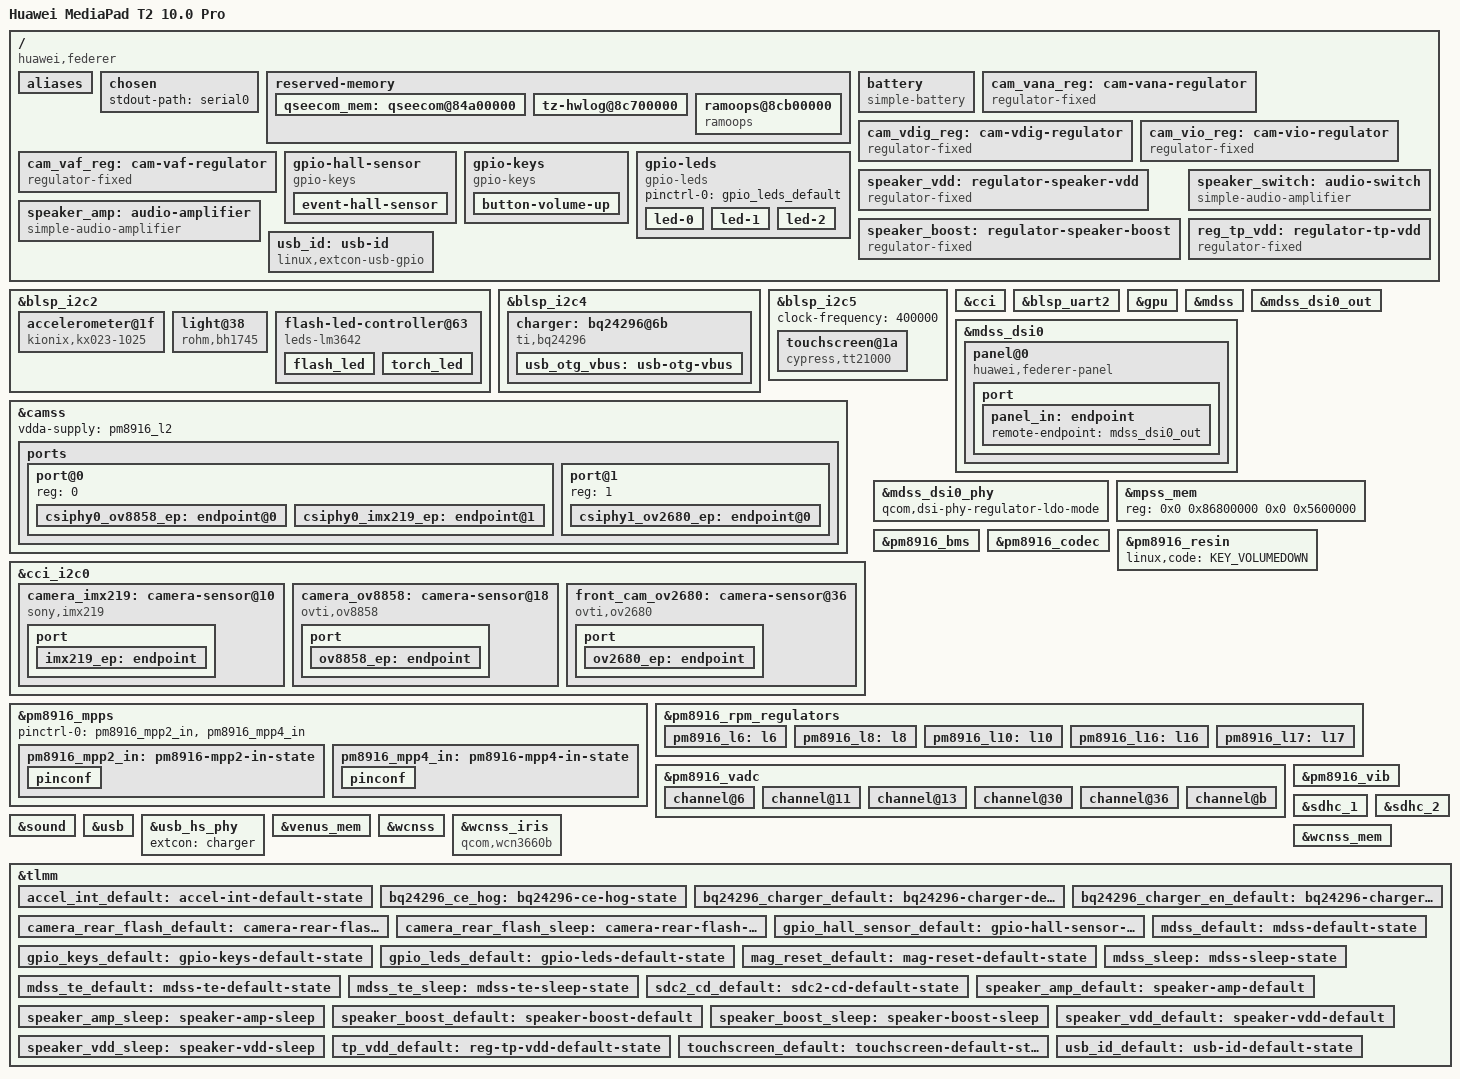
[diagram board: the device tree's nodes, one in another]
// SPDX-License-Identifier: GPL-2.0-only

/dts-v1/;

#include "msm8939-pm8916.dtsi"
#include "msm8916-modem-qdsp6.dtsi"

#include <dt-bindings/gpio/gpio.h>
#include <dt-bindings/input/input.h>
#include <dt-bindings/interrupt-controller/irq.h>
#include <dt-bindings/leds/common.h>
#include <dt-bindings/pinctrl/qcom,pmic-gpio.h>
#include <dt-bindings/pinctrl/qcom,pmic-mpp.h>

/ {
	model = "Huawei MediaPad T2 10.0 Pro";
	compatible = "huawei,federer", "qcom,msm8939";
	chassis-type = "tablet";

	aliases {
		mmc0 = &sdhc_1; /* eMMC */
		mmc1 = &sdhc_2; /* SD card */
		serial0 = &blsp_uart2;
		i2c0 = &blsp_i2c2;
	};

	chosen {
		stdout-path = "serial0";
	};

	reserved-memory {
		/*cont_splash_mem: framebuffer@83000000 {
			compatible = "removed-dma-pool";
			reg = <0x0 0x83000000 0x0 0x1A00000>;
			no-map;
		};*/

		qseecom_mem: qseecom@84a00000 {
			reg = <0x0 0x84a00000 0x0 0x1600000>;
			no-map;
		};

		tz-hwlog@8c700000 {
			reg = <0x0 0x8c700000 0x0 0x400000>;
			no-map;
		};

		ramoops@8cb00000 {
			compatible = "ramoops";
			reg = <0x0 0x8cb00000 0x0 0x200000>;

			record-size = <0x10000>;
			console-size = <0x100000>;
			ftrace-size = <0>;
		};
	};

	battery: battery {
		compatible = "simple-battery";
		device-chemistry = "lithium-ion-polymer";

		voltage-min-design-microvolt = <3350000>;
		voltage-max-design-microvolt = <4350000>;
		energy-full-design-microwatt-hours = <24700000>;
		charge-full-design-microamp-hours = <6500000>;

		factory-internal-resistance-micro-ohms = <118000>;

		precharge-current-microamp = <1300000>;
		charge-term-current-microamp = <260000>; //4%(from vendor dts)

		ocv-capacity-celsius = <(-25) 0 25>;
		/* table for -20 degree Celsius  data from HB26A510EBC_GY_SWD-4v35-6500mah.dtsi*/
		ocv-capacity-table-0 =  <4316000 100>,  <4200000 95>,  <4124000 90>,
			<4025000 85>,  <3964000 80>,  <3918000 75>,  <3883000 70>,
 			<3857000 65>,  <3836000 60>,  <3817000 55>,  <3800000 50>,
			 <3785000 45>,  <3770000 40>,  <3754000 35>,  <3737000 30>,
			 <3717000 25>,  <3694000 20>,  <3669000 16>,  <3645000 13>,
			 <3628000 11>,  <3616000 10>,  <3604000 9>,  <3586000 8>,
			 <3568000 7>,  <3544000 6>,  <3516000 5>,  <3478000 4>,
			 <3428000 3>,  <3360000 2>,  <3250000 1>,  <3000000 0>;
		/* table for 0 degree Celsius */
		ocv-capacity-table-1 =  <4315000 100>, <4250000 95>, <4190000 90>,
			<4136000 85>, <4085000 80>, <4032000 75>, <3957000 70>,
			<3918000 65>, <3885000 60>, <3854000 55>, <3828000 50>,
			<3806000 45>, <3790000 40>, <3777000 35>, <3765000 30>,
			<3751000 25>, <3732000 20>, <3712000 16>, <3698000 13>,
			<3690000 11>, <3686000 10>, <3680000 9>, <3674000 8>,
			<3664000 7>, <3648000 6>, <3623000 5>, <3584000 4>,
			<3530000 3>, <3449000 2>, <3316000 1>, <3000000 0>;
		/* table for 25 degree Celsius */
		ocv-capacity-table-2 = <4315000 100>, <4260000 95>, <4204000 90>,
			<4150000 85>, <4098000 80>, <4054000 75>, <3988000 70>,
			<3953000 65>, <3910000 60>, <3868000 55>, <3838000 50>,
			<3816000 45>, <3798000 40>, <3782000 35>, <3769000 30>,
			<3754000 25>, <3736000 20>, <3716000 16>, <3696000 13>,
			<3688000 11>, <3686000 10>, <3684000 9>, <3682000 8>,
			<3678000 7>, <3668000 6>, <3644000 5>, <3600000 4>,
			<3540000 3>, <3458000 2>, <3325000 1>, <3000000 0>;
	};

	cam_vana_reg: cam-vana-regulator {
		compatible = "regulator-fixed";
		regulator-name = "cam_vana";
		gpio = <&tlmm 110 GPIO_ACTIVE_HIGH>;
		//pinctrl-0 = <&cam_sensor_vana_default>;
		//pinctrl-names = "default";
		enable-active-high;
		regulator-always-on;
	};

	cam_vdig_reg: cam-vdig-regulator {
		compatible = "regulator-fixed";
		regulator-name = "cam_vdig";
		gpio = <&tlmm 121 GPIO_ACTIVE_HIGH>;
		//pinctrl-0 = <&cam_sensor_vdig_default>;
		//pinctrl-names = "default";
		enable-active-high;
	};

	cam_vio_reg: cam-vio-regulator {
		compatible = "regulator-fixed";
		regulator-name = "cam_vio";
		gpio = <&tlmm 114 GPIO_ACTIVE_HIGH>;
		//pinctrl-0 = <&cam_sensor_vdio_default>;
		//pinctrl-names = "default";
		enable-active-high;
	};

	/* AF_PWDM */
	cam_vaf_reg: cam-vaf-regulator {
		compatible = "regulator-fixed";
		regulator-name = "cam_vaf";
		vin-supply = <&pm8916_l10>;
		gpio = <&tlmm 120 GPIO_ACTIVE_HIGH>;
		enable-active-high;
		regulator-always-on;
	};

	gpio-hall-sensor {
		compatible = "gpio-keys";

		pinctrl-0 = <&gpio_hall_sensor_default>;
		pinctrl-names = "default";

		label = "GPIO Hall Effect Sensor";

		event-hall-sensor {
			label = "Hall Effect Sensor";
			gpios = <&tlmm 69 GPIO_ACTIVE_LOW>;
			linux,input-type = <EV_SW>;
			linux,code = <SW_LID>;
			linux,can-disable;
		};
	};

	gpio-keys {
		compatible = "gpio-keys";

		pinctrl-0 = <&gpio_keys_default>;
		pinctrl-names = "default";

		label = "GPIO Buttons";

		button-volume-up {
			label = "Volume Up";
			gpios = <&tlmm 107 GPIO_ACTIVE_LOW>;
			linux,code = <KEY_VOLUMEUP>;
		};
	};

	gpio-leds {
		compatible = "gpio-leds";

		pinctrl-0 = <&gpio_leds_default>;
		pinctrl-names = "default";

		led-0 {
			gpios = <&tlmm 8 GPIO_ACTIVE_HIGH>;
			color = <LED_COLOR_ID_RED>;
			default-state = "off";
			function = LED_FUNCTION_INDICATOR;
			retain-state-suspended;
		};

		led-1 {
			gpios = <&tlmm 9 GPIO_ACTIVE_HIGH>;
			color = <LED_COLOR_ID_GREEN>;
			default-state = "off";
			function = LED_FUNCTION_INDICATOR;
			retain-state-suspended;
		};

		led-2 {
			gpios = <&tlmm 10 GPIO_ACTIVE_HIGH>;
			color = <LED_COLOR_ID_BLUE>;
			default-state = "off";
			function = LED_FUNCTION_INDICATOR;
			retain-state-suspended;
		};
	};

	/* Basis-Spannung (GPIO 0) - Muss bei Kopfhörer UND Lautsprecher ON sein */
	speaker_vdd: regulator-speaker-vdd {
		compatible = "regulator-fixed";
		regulator-name = "speaker_vdd";
		gpio = <&tlmm 0 GPIO_ACTIVE_HIGH>;
		enable-active-high;
		regulator-always-on;

		pinctrl-names = "default", "sleep";
		pinctrl-0 = <&speaker_vdd_default>;
		pinctrl-1 = <&speaker_vdd_sleep>;
	};

	/* Boost-Spannung (GPIO 2) - Nur bei Lautsprecher ON, bei Kopfhörer OFF */
	speaker_boost: regulator-speaker-boost {
		compatible = "regulator-fixed";
		regulator-name = "speaker_boost";
		gpio = <&tlmm 2 GPIO_ACTIVE_HIGH>;
		enable-active-high;
		
		/* Hängt an VDD, kann aber unabhängig abgeschaltet werden! */
		vin-supply = <&speaker_vdd>; 

		pinctrl-names = "default", "sleep";
		pinctrl-0 = <&speaker_boost_default>;
		pinctrl-1 = <&speaker_boost_sleep>;
	};

	/* Der Umschalter (GPIO 1) - Nutzt VDD (GPIO 0) */
	speaker_switch: audio-switch {
		compatible = "simple-audio-amplifier";
		
		/* Dadurch bleibt der Schalter auch bei Kopfhörern (Boost=OFF) unter Spannung (VDD=ON) */
		VCC-supply = <&speaker_vdd>; 
		enable-gpios = <&tlmm 1 GPIO_ACTIVE_HIGH>;
		
		sound-name-prefix = "Speaker Switch";
	};

	/* Der End-Verstärker (GPIO 3) - Hängt am Boost (GPIO 2) */
	speaker_amp: audio-amplifier {
		compatible = "simple-audio-amplifier";
		VCC-supply = <&speaker_boost>; 
		enable-gpios = <&tlmm 3 GPIO_ACTIVE_HIGH>;
		startup-delay-us = <200000>; 

		pinctrl-names = "default", "sleep";
		pinctrl-0 = <&speaker_amp_default>;
		pinctrl-1 = <&speaker_amp_sleep>;

		sound-name-prefix = "Speaker";
	};

	reg_tp_vdd: regulator-tp-vdd {
		compatible = "regulator-fixed";
		regulator-name = "tp_vdd";

		vin-supply = <&pm8916_l17>;
		regulator-min-microvolt = <1850000>;
		regulator-max-microvolt = <1850000>;
		gpio = <&tlmm 112 GPIO_ACTIVE_HIGH>;
		enable-active-high;
		regulator-always-on;
	};

	usb_id: usb-id {
		compatible = "linux,extcon-usb-gpio";
		id-gpios = <&tlmm 117 GPIO_ACTIVE_HIGH>;
		pinctrl-0 = <&usb_id_default>;
		pinctrl-names = "default";
	};
};

&blsp_i2c2 {
	status = "okay";

	accelerometer@1f {
		compatible = "kionix,kx023-1025";
		reg = <0x1f>;

		vdd-supply = <&pm8916_l17>;
		vddio-supply = <&pm8916_l6>;
		pinctrl-0 = <&accel_int_default>;
		pinctrl-names = "default";
		mount-matrix =  "-1", "0", "0",
				"0", "-1", "0",
				"0", "0", "1";
	};

	light@38 {
		compatible = "rohm,bh1745";
		reg = <0x38>;
		vdd-supply = <&pm8916_l17>;
		vio-supply = <&pm8916_l6>;
	};

	flash-led-controller@63 {
		compatible = "leds-lm3642";
		reg = <0x63>;

		pinctrl-0 = <&camera_rear_flash_default>;
		pinctrl-1 = <&camera_rear_flash_sleep>;
		pinctrl-names = "default","sleep";

		//gpios = <&tlmm 86 GPIO_ACTIVE_HIGH>,<&tlmm 31 GPIO_ACTIVE_HIGH >;

		flash_led {
			linux,default-trigger = "flash";
			function = LED_FUNCTION_FLASH;
			color = <LED_COLOR_ID_WHITE>;
			gpios = <&tlmm 86 GPIO_ACTIVE_HIGH>;
			led-sources = <0 1>;
		};
		torch_led {
			linux,default-trigger = "torch";
			function = LED_FUNCTION_TORCH;
			color = <LED_COLOR_ID_WHITE>;
			gpios = <&tlmm 31 GPIO_ACTIVE_HIGH >;
			led-sources = <0 0>;
		};
	};

	/*flash_lm3642:qcom,led-flash@63 { //original camera flash
		reg = <0x63>;
		cell-index = <0>;
		qcom,slave-id = <0xC6 0x00 0x0011>;
		compatible = "ti,lm3642";
		label = "lm3642";
		qcom,flash-type = <1>;
		pinctrl-names = "cam_flash_default","cam_flash_suspend";
		pinctrl-0 = <&lm3642_en_default>;
		pinctrl-1 = <&lm3642_en_suspend>;
		gpios = <&msm_gpio 86 0>,
			<&msm_gpio 31 0>;
		qcom,gpio-flash-en = <0>;
		qcom,gpio-flash-now = <1>;
		qcom,gpio-req-tbl-num = <0 1>;
		qcom,gpio-req-tbl-flags = <0 0>;
		qcom,gpio-req-tbl-label = "FLASH_EN",
			"FLASH_NOW";
	};*/
};

&blsp_i2c4 {
	status = "okay";
	
	charger: bq24296@6b {
		compatible = "ti,bq24296";
		reg = <0x6b>;

		interrupt-parent = <&tlmm>;
		interrupts = <62 IRQ_TYPE_EDGE_FALLING>;

		pinctrl-names = "default";
		pinctrl-0 = <&bq24296_charger_default>;

		monitored-battery = <&battery>;
		ti,system-minimum-microvolt = <3300000>;
		omit-battery-class;

		usb_otg_vbus: usb-otg-vbus {
			regulator-name = "usb_otg_vbus";
			regulator-min-microvolt = <5000000>;
			regulator-max-microvolt = <5000000>;
		};
	};
};

&blsp_i2c5 {
	status = "okay";
	clock-frequency = <400000>;

	touchscreen@1a {
		compatible = "cypress,tt21000";
		reg = <0x1a>;

		interrupt-parent = <&tlmm>;
		interrupts = <13 IRQ_TYPE_EDGE_FALLING>;

		reset-gpios = <&tlmm 12 GPIO_ACTIVE_LOW>;

		vdd-supply = <&reg_tp_vdd>;
		vddio-supply = <&pm8916_l16>;

		pinctrl-0 = <&touchscreen_default>;
		pinctrl-names = "default";
	};
};

&camss {
	vdda-supply = <&pm8916_l2>;
	status = "okay";

	ports {
		port@0 {
			reg = <0>;
			#address-cells = <1>;
			#size-cells = <0>;

			csiphy0_ov8858_ep: endpoint@0 {
				reg = <0>;
				clock-lanes = <7>;
				data-lanes = <0 1 2 3>;
				remote-endpoint = <&ov8858_ep>;
			};

			csiphy0_imx219_ep: endpoint@1 {
				reg = <1>;
				clock-lanes = <7>;
				data-lanes = <0 1 2 3>;
				remote-endpoint = <&imx219_ep>;
			};
		};

		port@1 { // front ov2680_byd_bm2920b_pad(cmi) gc2355_ofilm_ohw2f03_pad(boe)
			reg = <1>;
			#address-cells = <1>;
			#size-cells = <0>;

			csiphy1_ov2680_ep: endpoint@0 {
				reg = <0>;
				clock-lanes = <7>;
				data-lanes = <0>;
				remote-endpoint = <&ov2680_ep>;
			};

			/*csiphy1_gc2355_ep: endpoint@1 {
				reg = <1>;
				clock-lanes = <7>;
				data-lanes = <0>;
				remote-endpoint = <&gc2355_ep>;
			};*/
		};
	};
};

&cci {
	status = "okay";
};

&cci_i2c0 {
	camera_imx219: camera-sensor@10 {
		compatible = "sony,imx219";
		reg = <0x10>;

		clocks = <&gcc GCC_CAMSS_MCLK0_CLK>;
		clock-names = "xclk";

		reset-gpios = <&tlmm 35 GPIO_ACTIVE_LOW>;

		VANA-supply = <&cam_vana_reg>;
		VDIG-supply = <&cam_vdig_reg>;
		VDDL-supply = <&cam_vio_reg>;

		pinctrl-0 = <&camera_rear_default>;
		pinctrl-names = "default";

		orientation = <1>;
		rotation = <90>;

		port {
			imx219_ep: endpoint {
				remote-endpoint = <&csiphy0_imx219_ep>;
				data-lanes = <0 1 2 3>;
				link-frequencies = /bits/ 64 <364000000>;
			};
		};
	};

	camera_ov8858: camera-sensor@18 {
		compatible = "ovti,ov8858";
		reg = <0x18>;

		clocks = <&gcc GCC_CAMSS_MCLK0_CLK>;
		clock-names = "xvclk";
		assigned-clocks = <&gcc GCC_CAMSS_MCLK0_CLK>;
		assigned-clock-rates = <24000000>;

		reset-gpios = <&tlmm 35 GPIO_ACTIVE_LOW>;
		powerdown-gpios  = <&tlmm 34 GPIO_ACTIVE_HIGH>;

		dovdd-supply = <&cam_vio_reg>;
		avdd-supply = <&cam_vana_reg>;
		dvdd-supply = <&cam_vdig_reg>;

		//pinctrl-0 = <&camera_rear_default>;
		//pinctrl-names = "default";

		orientation = <1>;
		rotation = <90>;

		port {
			ov8858_ep: endpoint {
				remote-endpoint = <&csiphy0_ov8858_ep>;
				data-lanes = <0 1 2 3>;
				link-frequencies = /bits/ 64 <360000000>;
			};
		};
	};

	front_cam_ov2680: camera-sensor@36 {
		compatible = "ovti,ov2680";
		reg = <0x36>;
		clocks = <&gcc GCC_CAMSS_MCLK1_CLK>;
		clock-names = "xvclk";

		reset-gpios = <&tlmm 28 GPIO_ACTIVE_LOW>;
		powerdown-gpios = <&tlmm 33 GPIO_ACTIVE_HIGH>;

		DOVDD-supply = <&cam_vio_reg>;
		AVDD-supply = <&cam_vana_reg>;
		DVDD-supply = <&cam_vio_reg>;

		pinctrl-0 = <&camera_front_default>;
		pinctrl-names = "default";

		port {
			ov2680_ep: endpoint {
				remote-endpoint = <&csiphy1_ov2680_ep>;
				data-lanes = <0>;
				link-frequencies = /bits/ 64 <331200000>;
			};
		};
	};

	// HINT: Erfordert den manuell importierten gc2355.c Treiber
	/*
	front_cam_gc2355: camera-sensor@3c {
		compatible = "galaxycore,gc2355";
		reg = <0x3c>;

		clocks = <&gcc GCC_CAMSS_MCLK1_CLK>;
		clock-names = "xclk";

		reset-gpios = <&tlmm 28 GPIO_ACTIVE_LOW>;
		powerdown-gpios = <&tlmm 33 GPIO_ACTIVE_HIGH>;

		VANA-supply = <&cam_vana_reg>;
		VDIO-supply = <&cam_vio_reg>;

		pinctrl-0 = <&camera_front_default>;
		pinctrl-names = "default";

		port {
			gc2355_ep: endpoint {
				remote-endpoint = <&csiphy1_gc2355_ep>;
				data-lanes = <0>;
				link-frequencies = /bits/ 64 <240000000>;
			};
		};
	};*/
};

&blsp_uart2 {
	pinctrl-0 = <&blsp_uart2_console_default>;
	pinctrl-1 = <&blsp_uart2_console_sleep>;
	pinctrl-names = "default", "sleep";
	status = "okay";
};

&gpu {
	status = "okay";
};

&mdss {
	status = "okay";
};

&mdss_dsi0 {
	pinctrl-0 = <&mdss_default &mdss_te_default>;
	pinctrl-1 = <&mdss_sleep &mdss_te_default>;
	pinctrl-names = "default", "sleep";
	status = "okay";

	panel@0 {
		reg = <0>;
		compatible = "huawei,federer-panel";

		vddio-supply = <&pm8916_l6>;

		vled-gpios = <&tlmm 97 GPIO_ACTIVE_HIGH>;
		blk-gpios = <&tlmm 109 GPIO_ACTIVE_HIGH>;
		panel-gpios = <&tlmm 32 GPIO_ACTIVE_HIGH>;

		reset-gpios = <&tlmm 25 GPIO_ACTIVE_LOW>;

		port {
			panel_in: endpoint {
				remote-endpoint = <&mdss_dsi0_out>;
			};
		};
	};
};

&mdss_dsi0_out {
	data-lanes = <0 1 2 3>;
	remote-endpoint = <&panel_in>;
};

&mdss_dsi0_phy {
	qcom,dsi-phy-regulator-ldo-mode;
	status = "okay";
};

&mpss_mem {
	reg = <0x0 0x86800000 0x0 0x5600000>;
	//reg = <0x0 0x86800000 0x0 0x5600000>;
	//reg = <0x0 0x86800000 0x0 0x2b00000>;
};

&pm8916_bms {
	monitored-battery = <&battery>;
	power-supplies = <&charger>;

	status = "okay";
};

&pm8916_codec {
	qcom,micbias-lvl = <2800>;
	qcom,mbhc-vthreshold-low = <75 150 237 450 500>;
	qcom,mbhc-vthreshold-high = <75 150 237 450 500>;
	qcom,micbias1-ext-cap;
	qcom,hphl-jack-type-normally-open;

	status = "okay";
};

&pm8916_mpps {
	pinctrl-names = "default";
	pinctrl-0 = <&pm8916_mpp2_in &pm8916_mpp4_in>;

	pm8916_mpp2_in: pm8916-mpp2-in-state {
		pinconf {
			pins = "mpp2";
			function = "analog"; //input
			qcom,amux-route = <1>; //PMIC_MPP_AMUX_ROUTE_CH6
		};
	};

	pm8916_mpp4_in: pm8916-mpp4-in-state {
		pinconf {
			pins = "mpp4";
			function = "analog"; //input
			qcom,amux-route = <3>; //PMIC_MPP_AMUX_ROUTE_CH8
		};
	};
};

&pm8916_resin {
	linux,code = <KEY_VOLUMEDOWN>;
	status = "okay";
};

&pm8916_rpm_regulators {
	pm8916_l6: l6 {
		regulator-min-microvolt = <1800000>;
		regulator-max-microvolt = <1800000>;
		regulator-always-on; 
		regulator-boot-on;
	};

	pm8916_l8: l8 {
		regulator-min-microvolt = <2950000>;
		regulator-max-microvolt = <2950000>;
	};

	pm8916_l10: l10 {
		regulator-min-microvolt = <2700000>;
		regulator-max-microvolt = <2800000>;
	};

	pm8916_l16: l16 {
		regulator-min-microvolt = <1800000>;
		regulator-max-microvolt = <1800000>;
		regulator-boot-on;
	};

	pm8916_l17: l17 {
		regulator-min-microvolt = <2850000>;
		regulator-max-microvolt = <2850000>;
		regulator-always-on; 
		regulator-boot-on;
	};
};

&pm8916_vadc {
	channel@6 {
		reg = <VADC_VBAT_SNS>;
		qcom,pre-scaling = <1 3>;
		//qcom,pre-scaling = <0x00000001 0x00000001>; /*hex*/
		//qcom,pre-scaling = /bits/ 8 <0x00 0x00 0x00 0x01 0x00 0x00 0x00 0x03>;
		label = "vbat_sns";
	};

	/* cam therm */
	channel@11 {
		reg = <VADC_P_MUX2_1_1>;
		qcom,decimation = <512>;
		qcom,pre-scaling = <1 1>;
		//qcom,ratiometric;
		qcom,hw-settle-time = <200>;
		qcom,avg-samples = <1>;
		label = "mpp2_div1";
	};

	/* cpu therm */
	channel@13 {
		reg = <VADC_P_MUX4_1_1>;
		qcom,decimation = <512>;
		qcom,pre-scaling = <1 1>;
		//qcom,ratiometric;
		qcom,hw-settle-time = <200>;
		qcom,avg-samples = <1>;
		label = "mpp4_div1";
	};

	channel@30 {
		reg = <VADC_LR_MUX1_BAT_THERM>;
		qcom,pre-scaling = <1 1>;
		qcom,ratiometric;
		qcom,hw-settle-time = <200>;
		qcom,avg-samples = <1>;
		label = "batt_therm";
	};

	/* pa therm0 */
	channel@36 {
		reg = <VADC_LR_MUX7_HW_ID>;
		qcom,pre-scaling = <1 1>;
		qcom,ratiometric;
		qcom,hw-settle-time = <200>;
		label = "pa_therm0";
	};

	channel@b {
		reg = <VADC_CHG_TEMP>;
		//reg = <0xb>;
		qcom,pre-scaling = <1 1>;
		qcom,hw-settle-time = <0>;
		label = "chg_temp";
	};
};

&pm8916_vib {
	status = "okay";
};

&sdhc_1 {
	status = "okay";
};

&sdhc_2 {
	pinctrl-0 = <&sdc2_default &sdc2_cd_default>;
	pinctrl-1 = <&sdc2_sleep &sdc2_cd_default>;
	pinctrl-names = "default", "sleep";

	cd-gpios = <&tlmm 38 GPIO_ACTIVE_LOW>;

	status = "okay";
};

&sound {
	model = "wt86528";
	widgets =
		"Speaker", "Speaker",
		"Headphone", "Headphones";

		/* Wir verpacken den VDD-Regulator als Audio-Widget, damit ALSA ihn direkt schalten kann */
		//"Regulator", "Speaker VDD Reg";

	pin-switches = "Speaker", "Speaker Switch";
	
	audio-routing =
		/* Lautsprecher-Kette (schaltet alles kaskadiert ein) */
		"Speaker", "Speaker OUTL",
		"Speaker", "Speaker OUTR",
		"Speaker INL", "Speaker Switch OUTL",
		"Speaker INR", "Speaker Switch OUTR",
		"Speaker Switch INL", "HPH_L",
		"Speaker Switch INR", "HPH_R",
		
		/* Kopfhörer-Kette zwingt das VDD-Regulator-Widget auf ON */
		"Headphones", "HPH_L",
		"Headphones", "HPH_R",
		//"Headphones", "Speaker VDD Reg", /* Zwingt GPIO 0 auf ON bei Kopfhörern! */
		
		"AMIC1", "MIC BIAS External1",
		"AMIC2", "MIC BIAS External2",
		"AMIC3", "MIC BIAS External1";
		
	aux-devs = <&speaker_amp>, <&speaker_switch>;
	status = "okay";
};

&usb {
	//extcon = <&usb_id>, <&usb_id>;
	extcon = <&charger>, <&usb_id>;
	vbus-supply = <&usb_otg_vbus>;

	status = "okay";
};

&usb_hs_phy {
	//extcon = <&usb_id>;
	extcon = <&charger>;
};

&venus_mem {
	status = "okay";
};

&wcnss {
	status = "okay";
};

&wcnss_iris {
	compatible = "qcom,wcn3660b";
};

&wcnss_mem {
	status = "okay";
};

&tlmm {
	accel_int_default: accel-int-default-state {
		pins = "gpio115";
		function = "gpio";
		drive-strength = <2>;
		bias-disable;
	};

	bq24296_ce_hog: bq24296-ce-hog-state {
		gpio-hog;
		gpios = <108 GPIO_ACTIVE_HIGH>;
		output-high;
		line-name = "bq24296-charge-enable";
	};
	
	bq24296_charger_default: bq24296-charger-default-state  {
		pins = "gpio62";
		function = "gpio";
		drive-strength = <2>;
		bias-pull-up;
	};

	bq24296_charger_en_default: bq24296-charger-en-default-state  {
		pins = "gpio108";
		function = "gpio";
		drive-strength = <2>;
		bias-disable;
		//output-low;
	};

	camera_rear_flash_default: camera-rear-flash-default-state {
		pins = "gpio31", "gpio86";
		function = "gpio";
		drive-strength = <2>;
		bias-disable;
	};

	camera_rear_flash_sleep: camera-rear-flash-sleep-state {
		pins = "gpio31", "gpio86";
		function = "gpio";
		drive-strength = <2>;
		bias-pull-down;
	};

	gpio_hall_sensor_default: gpio-hall-sensor-default-state {
		pins = "gpio69";
		function = "gpio";
		drive-strength = <2>;
		bias-disable;
	};

	gpio_keys_default: gpio-keys-default-state {
		pins = "gpio107";
		function = "gpio";
		drive-strength = <2>;
		bias-pull-up;
	};

	gpio_leds_default: gpio-leds-default-state {
		pins = "gpio8", "gpio9", "gpio10";
		function = "gpio";
		drive-strength = <2>;
		bias-disable;
	};

	mag_reset_default: mag-reset-default-state {
		pins = "gpio36";
		function = "gpio";
		drive-strength = <2>;
		bias-disable;
	};

	mdss_default: mdss-default-state {
		pins = "gpio25";
		function = "gpio";
		drive-strength = <8>;
		bias-disable;
	};

	mdss_sleep: mdss-sleep-state {
		pins = "gpio25";
		function = "gpio";
		drive-strength = <2>;
		bias-pull-down;
	};

	mdss_te_default: mdss-te-default-state {
		pins = "gpio24";
		//function = "gpio";
		function = "mdp_vsync";
		drive-strength = <2>;
		bias-disable;
	};

	mdss_te_sleep: mdss-te-sleep-state {
		pins = "gpio24";
		//function = "gpio";
		function = "mdp_vsync";
		drive-strength = <2>;
		bias-pull-down;
	};

	sdc2_cd_default: sdc2-cd-default-state {
		pins = "gpio38";
		function = "gpio";
		drive-strength = <2>;
		bias-disable;
	};

	/* GPIO 3 - Speaker Enable */
	speaker_amp_default: speaker-amp-default {
		pins = "gpio3";
		function = "gpio";
		drive-strength = <2>;
		bias-disable; /* Kein interner Widerstand, der Kernel steuert den Pin aktiv */
	};

	speaker_amp_sleep: speaker-amp-sleep {
		pins = "gpio3";
		function = "gpio";
		drive-strength = <2>;
		bias-pull-down; /* Zwingt den Pin im Standby sicher auf LOW (Masse) */
	};

	/* GPIO 2 - Speaker Boost */
	speaker_boost_default: speaker-boost-default {
		pins = "gpio2";
		function = "gpio";
		drive-strength = <2>;
		bias-pull-up;
	};

	speaker_boost_sleep: speaker-boost-sleep {
		pins = "gpio2";
		function = "gpio";
		drive-strength = <2>;
		bias-pull-down;
	};

	/* GPIO 0 - Speaker VDD */
	speaker_vdd_default: speaker-vdd-default {
		pins = "gpio0";
		function = "gpio";
		drive-strength = <2>;
		bias-pull-up;
	};

	speaker_vdd_sleep: speaker-vdd-sleep {
		pins = "gpio0";
		function = "gpio";
		drive-strength = <2>;
		bias-pull-down;
	};

	tp_vdd_default: reg-tp-vdd-default-state {
		pins = "gpio112";
		function = "gpio";
		drive-strength = <2>;
		bias-pull-up;
	};

	touchscreen_default: touchscreen-default-state {
		pins = "gpio12", "gpio13";
		function = "gpio";
		drive-strength = <2>;
		bias-disable;
	};

	usb_id_default: usb-id-default-state {
		pins = "gpio117";
		function = "gpio";
		drive-strength = <8>;
		bias-pull-up;
	};
};
